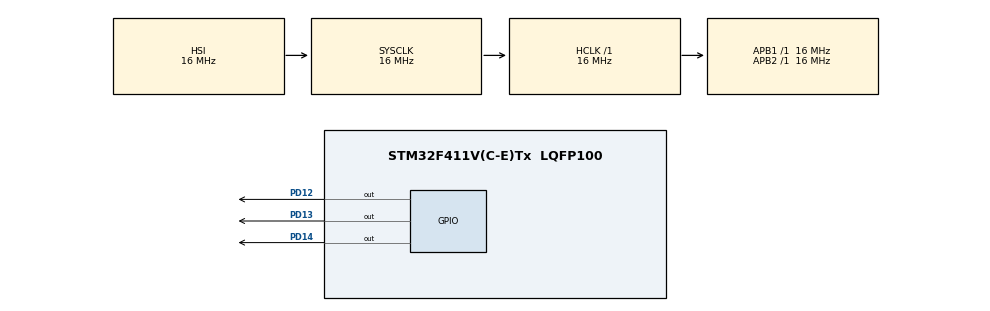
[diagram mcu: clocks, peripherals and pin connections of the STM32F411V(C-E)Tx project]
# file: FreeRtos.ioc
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Mcu.Family=STM32F4
FREERTOS.Queues01=temp,32,uint16_t,0,Dynamic,NULL,NULL
RCC.CortexFreq_Value=16000000
FREERTOS.Tasks01=task1,24,128,func1,Default,NULL,Dynamic,NULL,NULL;task2,8,128,func2,Default,NULL,Dynamic,NULL,NULL;task3,8,128,StartTask03,Default,NULL,Dynamic,NULL,NULL
ProjectManager.StackSize=0x400
VP_FREERTOS_VS_CMSIS_V2.Mode=CMSIS_V2
PD13.Signal=GPIO_Output
PA13.Signal=SYS_JTMS-SWDIO
ProjectManager.TargetToolchain=STM32CubeIDE
RCC.LSE_VALUE=32768
RCC.AHBFreq_Value=16000000
RCC.HSE_VALUE=25000000
board=custom
RCC.VCOOutputFreq_Value=192000000
RCC.APB2Freq_Value=16000000
PA14.Mode=Serial_Wire
PA13.Mode=Serial_Wire
Mcu.Name=STM32F411V(C-E)Tx
PD14.Signal=GPIO_Output
RCC.SYSCLKFreq_VALUE=16000000
Mcu.Package=LQFP100
PD12.Signal=GPIO_Output
PA14.Signal=SYS_JTCK-SWCLK
ProjectManager.HeapSize=0x200
RCC.HSI_VALUE=16000000
NVIC.PriorityGroup=NVIC_PRIORITYGROUP_4
RCC.APB1Freq_Value=16000000

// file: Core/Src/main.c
/* USER CODE BEGIN Header */
/**
  ******************************************************************************
  * @file           : main.c
  * @brief          : Main program body
  ******************************************************************************
  * @attention
  *
  * <h2><center>&copy; Copyright (c) 2024 STMicroelectronics.
  * All rights reserved.</center></h2>
  *
  * This software component is licensed by ST under BSD 3-Clause license,
  * the "License"; You may not use this file except in compliance with the
  * License. You may obtain a copy of the License at:
  *                        opensource.org/licenses/BSD-3-Clause
  *
  ******************************************************************************
  */
/* USER CODE END Header */
#include "main.h"
#include "cmsis_os.h"

/* Definitions for task1 */
osThreadId_t task1Handle;
const osThreadAttr_t task1_attributes = {
  .name = "task1",
  .stack_size = 128 * 4,
  .priority = (osPriority_t) osPriorityNormal,
};
/* Definitions for task2 */
osThreadId_t task2Handle;
const osThreadAttr_t task2_attributes = {
  .name = "task2",
  .stack_size = 128 * 4,
  .priority = (osPriority_t) osPriorityLow,
};
/* Definitions for task3 */
osThreadId_t task3Handle;
const osThreadAttr_t task3_attributes = {
  .name = "task3",
  .stack_size = 128 * 4,
  .priority = (osPriority_t) osPriorityLow,
};
/* Definitions for temp */
osMessageQueueId_t tempHandle;
const osMessageQueueAttr_t temp_attributes = {
  .name = "temp"
};

void SystemClock_Config(void);
static void MX_GPIO_Init(void);
void func1(void *argument);
void func2(void *argument);
void StartTask03(void *argument);

int main(void)
{

  /* MCU Configuration--------------------------------------------------------*/

  /* Reset of all peripherals, Initializes the Flash interface and the Systick. */
  HAL_Init();

  /* Configure the system clock */
  SystemClock_Config();

  /* Initialize all configured peripherals */
  MX_GPIO_Init();

  /* Init scheduler */
  osKernelInitialize();

  /* Create the queue(s) */
  /* creation of temp */
  tempHandle = osMessageQueueNew (32, sizeof(uint16_t), &temp_attributes);

  /* Create the thread(s) */
  /* creation of task1 */
  task1Handle = osThreadNew(func1, NULL, &task1_attributes);

  /* creation of task2 */
  task2Handle = osThreadNew(func2, NULL, &task2_attributes);

  /* creation of task3 */
  task3Handle = osThreadNew(StartTask03, NULL, &task3_attributes);

  /* Start scheduler */
  osKernelStart();

  /* We should never get here as control is now taken by the scheduler */
  /* Infinite loop */
  while (1)
  {

  }
}

void SystemClock_Config(void)
{
  RCC_OscInitTypeDef RCC_OscInitStruct = {0};
  RCC_ClkInitTypeDef RCC_ClkInitStruct = {0};

  /** Configure the main internal regulator output voltage
  */
  __HAL_RCC_PWR_CLK_ENABLE();
  __HAL_PWR_VOLTAGESCALING_CONFIG(PWR_REGULATOR_VOLTAGE_SCALE1);
  /** Initializes the RCC Oscillators according to the specified parameters
  * in the RCC_OscInitTypeDef structure.
  */
  RCC_OscInitStruct.OscillatorType = RCC_OSCILLATORTYPE_HSI;
  RCC_OscInitStruct.HSIState = RCC_HSI_ON;
  RCC_OscInitStruct.HSICalibrationValue = RCC_HSICALIBRATION_DEFAULT;
  RCC_OscInitStruct.PLL.PLLState = RCC_PLL_NONE;
  if (HAL_RCC_OscConfig(&RCC_OscInitStruct) != HAL_OK)
  {
    Error_Handler();
  }
  /** Initializes the CPU, AHB and APB buses clocks
  */
  RCC_ClkInitStruct.ClockType = RCC_CLOCKTYPE_HCLK|RCC_CLOCKTYPE_SYSCLK
                              |RCC_CLOCKTYPE_PCLK1|RCC_CLOCKTYPE_PCLK2;
  RCC_ClkInitStruct.SYSCLKSource = RCC_SYSCLKSOURCE_HSI;
  RCC_ClkInitStruct.AHBCLKDivider = RCC_SYSCLK_DIV1;
  RCC_ClkInitStruct.APB1CLKDivider = RCC_HCLK_DIV1;
  RCC_ClkInitStruct.APB2CLKDivider = RCC_HCLK_DIV1;

  if (HAL_RCC_ClockConfig(&RCC_ClkInitStruct, FLASH_LATENCY_0) != HAL_OK)
  {
    Error_Handler();
  }
}

static void MX_GPIO_Init(void)
{
  GPIO_InitTypeDef GPIO_InitStruct = {0};

  /* GPIO Ports Clock Enable */
  __HAL_RCC_GPIOD_CLK_ENABLE();
  __HAL_RCC_GPIOA_CLK_ENABLE();

  /*Configure GPIO pin Output Level */
  HAL_GPIO_WritePin(GPIOD, GPIO_PIN_12|GPIO_PIN_13|GPIO_PIN_14, GPIO_PIN_RESET);

  /*Configure GPIO pins : PD12 PD13 PD14 */
  GPIO_InitStruct.Pin = GPIO_PIN_12|GPIO_PIN_13|GPIO_PIN_14;
  GPIO_InitStruct.Mode = GPIO_MODE_OUTPUT_PP;
  GPIO_InitStruct.Pull = GPIO_NOPULL;
  GPIO_InitStruct.Speed = GPIO_SPEED_FREQ_LOW;
  HAL_GPIO_Init(GPIOD, &GPIO_InitStruct);

}

void func1(void *argument)
{
  /* USER CODE BEGIN 5 */
  /* Infinite loop */
  for(;;)
  {
	  HAL_GPIO_WritePin(GPIOD, GPIO_PIN_14, GPIO_PIN_SET);
    osDelay(1000);
    HAL_GPIO_WritePin(GPIOD, GPIO_PIN_14, GPIO_PIN_RESET);
        osDelay(1000);
  }
  /* USER CODE END 5 */
}

void func2(void *argument)
{
  /* USER CODE BEGIN func2 */
  /* Infinite loop */
	int temp = 0;
  for(;;)
  {
	  osMessageQueueGet(tempHandle,&temp, 0, 1000);
	  HAL_GPIO_WritePin(GPIOD, GPIO_PIN_12, GPIO_PIN_SET);
	  osDelay(500);

	  HAL_GPIO_WritePin(GPIOD, GPIO_PIN_12, GPIO_PIN_RESET);
	  osDelay(500);
  }
  /* USER CODE END func2 */
}

void StartTask03(void *argument)
{
  /* USER CODE BEGIN StartTask03 */
  /* Infinite loop */
	int i = 0;
  for(;;)
  {
	  i++;
	  osMessageQueuePut(tempHandle, &i, 0, 1000);
	  osDelay(1);
  }
  /* USER CODE END StartTask03 */
}

void Error_Handler(void)
{
  __disable_irq();
  while (1)
  {
  }
}

/************************ (C) COPYRIGHT STMicroelectronics *****END OF FILE****/
